VERSION ""

NS_ :

BS_:

BU_: IAP ODS _4WD BCM HUD DATC MDPS AAF_Tester AEMC SMK _4WD EPB CUBIS MTS TMU EVP CGW TPMS LPI DI_BOX SPAS EMS LCA TCU IBOX FATC AFLS FPCM SCC AHLS AVM ABS SNV OPI PGS SAS AAF Dummy LDWS_LKAS LVR ESC PSB CLU ECS ACU REA 4 + XXX 6 K 2

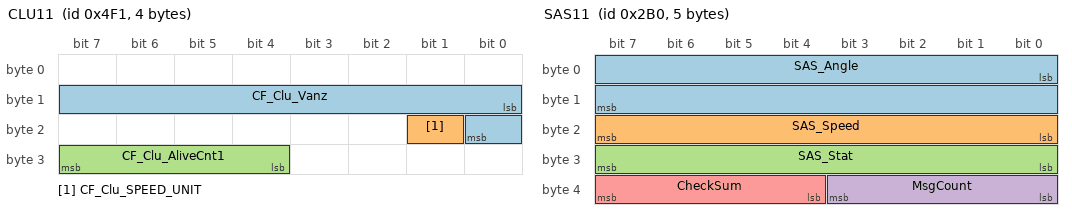
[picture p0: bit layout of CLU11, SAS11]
BO_ 1265 CLU11: 4 CLU
 SG_ CF_Clu_Vanz : 8|9@1+ (0.5,0) [0|255.5] "km/h or MPH" BCM,CUBIS,EMS,IBOX,LDWS_LKAS,MDPS,SCC
 SG_ CF_Clu_SPEED_UNIT : 17|1@1+ (1,0) [0|1] "" BCM,CUBIS,EMS,IBOX,LDWS_LKAS,MDPS,SCC
 SG_ CF_Clu_AliveCnt1 : 28|4@1+ (1,0) [0|15] "" AHLS,EMS,EPB,LDWS_LKAS,MDPS,SCC

BO_ 688 SAS11: 5 MDPS
 SG_ SAS_Angle : 0|16@1- (0.1,0) [-3276.8|3276.7] "Deg" _4WD,ACU,AFLS,AVM,CLU,ECS,EMS,ESC,IBOX,LCA,LDWS_LKAS,PGS,PSB,SCC,SPAS,TCU,_4WD,ACU,AFLS,AVM,BCM,CLU,ECS,EMS,ESC,IBOX,LCA,LDWS_LKAS,PGS,PSB,SCC,SPAS,TCU
 SG_ SAS_Speed : 16|8@1+ (4,0) [0|1016] "" AFLS,ECS,ESC,IBOX,LDWS_LKAS,SCC,SPAS,TCU,AFLS,ECS,ESC,IBOX,LDWS_LKAS,SCC,SPAS,TCU
 SG_ SAS_Stat : 24|8@1+ (1,0) [0|255] "" ECS,ESC,IBOX,LDWS_LKAS,PSB,SCC,SPAS,TCU,ECS,ESC,IBOX,LDWS_LKAS,PSB,SCC,SPAS,TCU
 SG_ MsgCount : 32|4@1+ (1,0) [0|15] "" ECS,ESC,IBOX,LDWS_LKAS,PSB,SCC,SPAS,ECS,ESC,IBOX,LDWS_LKAS,PSB,SCC,SPAS
 SG_ CheckSum : 36|4@1+ (1,0) [0|15] "" ECS,EMS,ESC,IBOX,LDWS_LKAS,PSB,SCC,SPAS,ECS,EMS,ESC,IBOX,LDWS_LKAS,PSB,SCC,SPAS

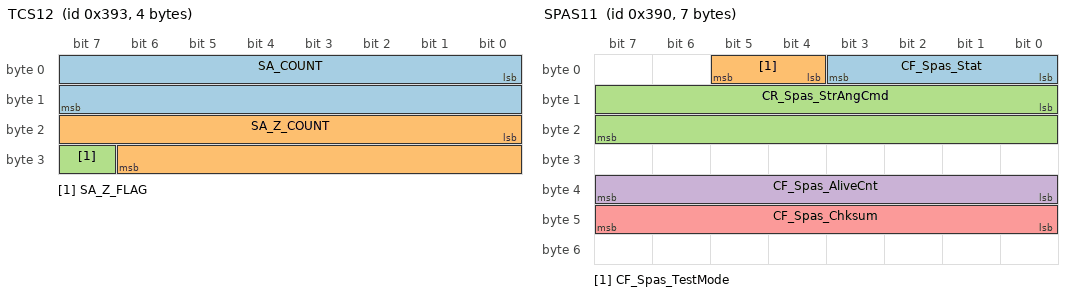
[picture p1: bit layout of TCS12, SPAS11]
BO_ 915 TCS12: 4 ESC
 SG_ SA_COUNT : 0|16@1+ (2,-32768) [-32768|98302] "" _4WD,ACU,MDPS
 SG_ SA_Z_COUNT : 16|15@1+ (2,-32768) [-32768|32766] "" _4WD,ACU,MDPS
 SG_ SA_Z_FLAG : 31|1@1+ (1,0) [0|1] "" _4WD,ACU,MDPS

BO_ 1170 EMS19: 8 EMS
 SG_ CF_Ems_AliveCounterEMS9 : 58|2@1+ (1,0) [0|3] "" AAF,ABS,CUBIS,ECS,EPB,IBOX,MDPS,REA,SCC,SMK,TCU
 SG_ CF_Ems_ChecksumEMS9 : 60|4@1+ (1,0) [0|15] "" AAF,ABS,CUBIS,ECS,EPB,IBOX,MDPS,REA,SCC,SMK,TCU

BO_ 912 SPAS11: 7 SPAS
 SG_ CF_Spas_Stat : 0|4@1+ (1,0) [0|15] "" ESC,MDPS
 SG_ CF_Spas_TestMode : 4|2@1+ (1,0) [0|3] "" MDPS
 SG_ CR_Spas_StrAngCmd : 8|16@1- (0.1,0) [-3276.8|3276.7] "" MDPS
 SG_ CF_Spas_AliveCnt : 32|8@1+ (1,0) [0|255] "" MDPS
 SG_ CF_Spas_Chksum : 40|8@1+ (1,0) [0|255] "" MDPS

BO_ 399 EMS_H12: 8 EMS
 SG_ CF_Ems_IsgStat : 35|3@1+ (1,0) [0|7] "" ABS,BCM,CLU,DATC,EPB,ESC,IBOX,LDWS_LKAS,MDPS,SMK,TCU

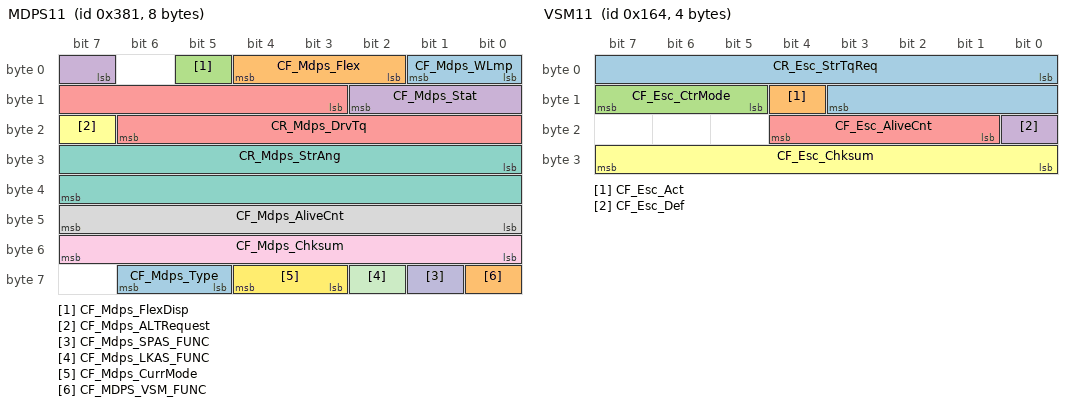
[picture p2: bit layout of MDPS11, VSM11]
BO_ 897 MDPS11: 8 MDPS
 SG_ CF_Mdps_WLmp : 0|2@1+ (1,0) [0|3] "" CLU,CUBIS,EMS,IBOX,SPAS
 SG_ CF_Mdps_Flex : 2|3@1+ (1,0) [0|3] "" CLU,LDWS_LKAS
 SG_ CF_Mdps_FlexDisp : 5|1@1+ (1,0) [0|1] "" CLU
 SG_ CF_Mdps_Stat : 7|4@1+ (1,0) [0|15] "" SPAS
 SG_ CR_Mdps_DrvTq : 11|12@1+ (1,-2048) [-2048|2046] "" SPAS
 SG_ CF_Mdps_ALTRequest : 23|1@1+ (1,0) [0|1] "" EMS
 SG_ CR_Mdps_StrAng : 24|16@1- (0.1,0) [-3276.8|3276.7] "Deg" SPAS
 SG_ CF_Mdps_AliveCnt : 40|8@1+ (1,0) [0|255] "" LDWS_LKAS,SPAS
 SG_ CF_Mdps_Chksum : 48|8@1+ (1,0) [0|255] "" LDWS_LKAS,SPAS
 SG_ CF_Mdps_SPAS_FUNC : 57|1@1+ (1,0) [0|1] "flag" SPAS
 SG_ CF_Mdps_LKAS_FUNC : 58|1@1+ (1,0) [0|1] "flag" LDWS_LKAS
 SG_ CF_Mdps_CurrMode : 59|2@1+ (1,0) [0|3] "" LDWS_LKAS
 SG_ CF_Mdps_Type : 61|2@1+ (1,0) [0|2] "" LDWS_LKAS,SPAS
 SG_ CF_MDPS_VSM_FUNC : 56|1@0+ (1,0) [0|1] "" XXX

BO_ 356 VSM11: 4 ESC
 SG_ CR_Esc_StrTqReq : 0|12@1+ (0.01,-20.48) [-20.48|20.47] "Nm" MDPS
 SG_ CF_Esc_Act : 12|1@1+ (1,0) [0|1] "" LDWS_LKAS,MDPS
 SG_ CF_Esc_CtrMode : 13|3@1+ (1,0) [0|7] "" MDPS
 SG_ CF_Esc_Def : 16|1@1+ (1,0) [0|1] "" MDPS
 SG_ CF_Esc_AliveCnt : 17|4@1+ (1,0) [0|15] "" LDWS_LKAS,MDPS
 SG_ CF_Esc_Chksum : 24|8@1+ (1,0) [0|255] "" LDWS_LKAS,MDPS

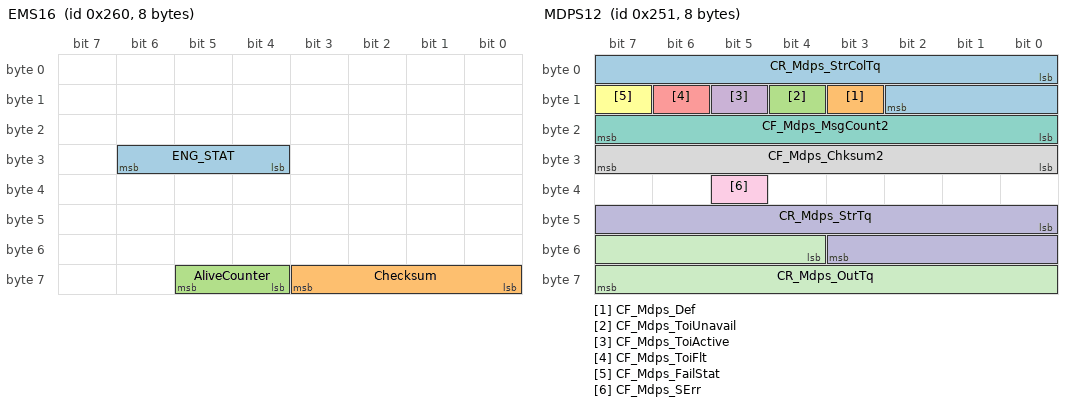
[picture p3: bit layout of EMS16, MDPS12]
BO_ 608 EMS16: 8 EMS
 SG_ ENG_STAT : 28|3@1+ (1,0) [0|7] "" ABS,AHLS,AVM,BCM,CLU,EPB,ESC,EVP,FPCM,IBOX,LCA,LDWS_LKAS,MDPS,SCC,SMK,TCU
 SG_ Checksum : 56|4@1+ (1,0) [0|15] "" ECS,IBOX,LDWS_LKAS,MDPS,SCC
 SG_ AliveCounter : 60|2@1+ (1,0) [0|3] "" IBOX,LDWS_LKAS,MDPS,SCC

BO_ 593 MDPS12: 8 MDPS
 SG_ CR_Mdps_StrColTq : 0|11@1+ (0.0078125,-8) [-8|7.9921875] "Nm" LDWS_LKAS
 SG_ CF_Mdps_Def : 11|1@1+ (1,0) [0|1] "" ESC
 SG_ CF_Mdps_ToiUnavail : 12|1@1+ (1,0) [0|1] "" LDWS_LKAS
 SG_ CF_Mdps_ToiActive : 13|1@1+ (1,0) [0|1] "" LDWS_LKAS
 SG_ CF_Mdps_ToiFlt : 14|1@1+ (1,0) [0|1] "" LDWS_LKAS
 SG_ CF_Mdps_FailStat : 15|1@1+ (1,0) [0|1] "" LDWS_LKAS
 SG_ CF_Mdps_MsgCount2 : 16|8@1+ (1,0) [0|255] "" ESC,LDWS_LKAS
 SG_ CF_Mdps_Chksum2 : 24|8@1+ (1,0) [0|255] "" ESC,LDWS_LKAS
 SG_ CF_Mdps_SErr : 37|1@1+ (1,0) [0|1] "" ESC
 SG_ CR_Mdps_StrTq : 40|12@1+ (0.01,-20.48) [-20.48|20.47] "Nm" ESC
 SG_ CR_Mdps_OutTq : 52|12@1+ (0.1,-204.8) [-204.8|204.7] "" ESC,LDWS_LKAS

BO_ 1345 CGW1: 8 BCM
 SG_ CF_Gway_IGNSw : 0|3@1+ (1,0) [0|7] "" AVM,CLU,ECS,EMS,EPB,ESC,IBOX,LVR,MDPS,SAS,SCC,ECS,EMS,EPB,ESC,IBOX,LVR,MDPS,SAS,SCC
 SG_ CF_Gway_InhibitRMT : 54|2@1+ (1,0) [0|3] "" EMS,EPB,ESC,IBOX,LCA,LDWS_LKAS,MDPS,PGS,SCC,SPAS,TPMS,EPB,ESC,IBOX,LCA,LDWS_LKAS,PGS,SCC,SPAS,TPMS

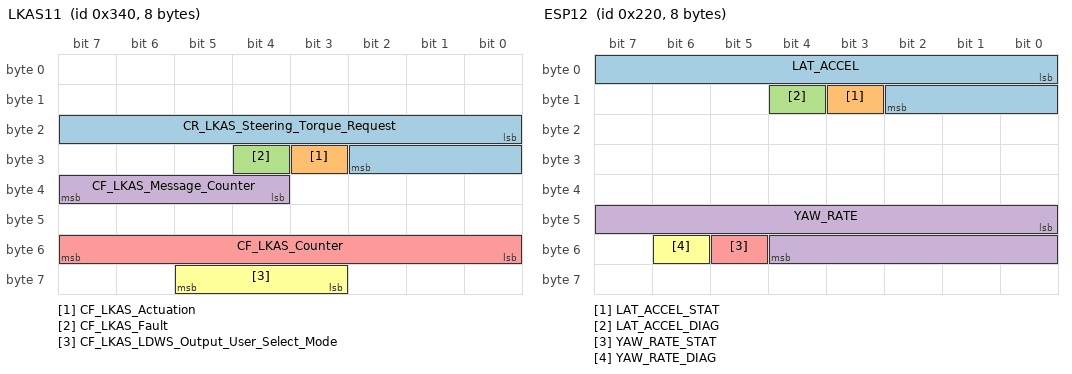
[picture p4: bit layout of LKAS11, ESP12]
BO_ 832 LKAS11: 8 LDWS_LKAS
 SG_ CR_LKAS_Steering_Torque_Request : 16|11@1+ (1,-1024) [-1024|1024] "" MDPS
 SG_ CF_LKAS_Actuation : 27|1@1+ (1,0) [0|1] "" MDPS
 SG_ CF_LKAS_Fault : 28|1@1+ (1,0) [0|1] "" MDPS
 SG_ CF_LKAS_Message_Counter : 36|4@1+ (1,0) [0|15] "" CLU,MDPS
 SG_ CF_LKAS_Counter : 48|8@1+ (1,0) [0|255] "" MDPS
 SG_ CF_LKAS_LDWS_Output_User_Select_Mode : 59|3@1+ (1,0) [0|7] "" CLU,MDPS

BO_ 544 ESP12: 8 ESC
 SG_ LAT_ACCEL : 0|11@1+ (0.01,-10.23) [-10.23|10.24] "m/s^2" _4WD,ECS,IBOX,LCA,LDWS_LKAS,MDPS,PSB,SCC,TCU
 SG_ LAT_ACCEL_STAT : 11|1@1+ (1,0) [0|1] "" _4WD,IBOX,LDWS_LKAS,MDPS,PSB,SCC,TCU
 SG_ LAT_ACCEL_DIAG : 12|1@1+ (1,0) [0|1] "" _4WD,IBOX,LDWS_LKAS,MDPS,PSB,SCC,TCU
 SG_ YAW_RATE : 40|13@1+ (0.01,-40.95) [-40.95|40.96] "" _4WD,AFLS,IBOX,LCA,LDWS_LKAS,MDPS,PSB,SCC,SPAS,TCU
 SG_ YAW_RATE_STAT : 53|1@1+ (1,0) [0|1] "" _4WD,AFLS,IBOX,LCA,LDWS_LKAS,MDPS,PSB,SCC,SPAS,TCU
 SG_ YAW_RATE_DIAG : 54|1@1+ (1,0) [0|1] "" _4WD,AFLS,IBOX,LCA,LDWS_LKAS,MDPS,PSB,SCC,SPAS,TCU

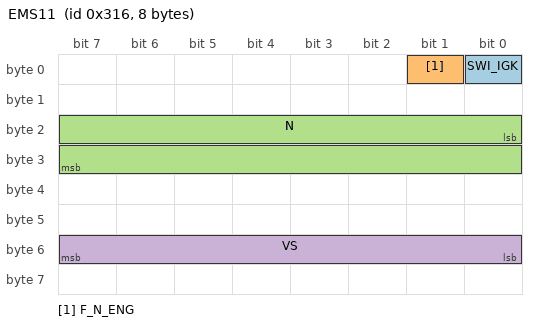
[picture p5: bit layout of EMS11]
BO_ 790 EMS11: 8 EMS
 SG_ SWI_IGK : 0|1@1+ (1,0) [0|1] "" _4WD,ABS,ACU,AHLS,CUBIS,DI_BOX,ECS,EPB,ESC,IBOX,LDWS_LKAS,MDPS,REA,SAS,SCC,TCU
 SG_ F_N_ENG : 1|1@1+ (1,0) [0|1] "" _4WD,ACU,AFLS,CLU,CUBIS,DATC,ECS,EPB,ESC,IBOX,MDPS,SCC,TCU
 SG_ N : 16|16@1+ (0.25,0) [0|16383.75] "rpm" _4WD,ACU,AFLS,CLU,CUBIS,DATC,ECS,EPB,ESC,FPCM,IBOX,MDPS,SCC,TCU
 SG_ VS : 48|8@1+ (1,0) [0|254] "km/h" _4WD,AAF,ACU,AHLS,BCM,CLU,DATC,ECS,EPB,IBOX,LCA,LDWS_LKAS,LVR,MDPS,ODS,SCC,SMK,SPAS,TCU,TPMS

BO_ 273 Telematic_Control_Unit_1: 8 TCU
 SG_ Gear_Selector_Display : 8|4@1+ (1,0) [0|15] "" _4WD,AFLS,AVM,BCM,CGW,CLU,CUBIS,ECS,EMS,EPB,ESC,IAP,IBOX,LCA,LDWS_LKAS,LVR,MDPS,PGS,SCC,SMK,SNV,SPAS,TPMS

BO_ 1292 CLU13: 8 CLU
 SG_ CF_Clu_DrivingModeSwi : 16|2@1+ (1,0) [0|3] "" DATC,ECS,EMS,ESC,IAP,MDPS,TCU
 SG_ CF_Clu_FlexSteerSW : 23|1@1+ (1,0) [0|1] "" MDPS

BO_ 870 366_EMS: 8 EMS
 SG_ VS : 40|8@1+ (1,0) [0|255] "km/h" MDPS
